# UPD70F3508 register map
Vendor: Renesas; Series: V850E2/Px4; File version: 1.0
CPU: other r0p0, little endian, no MPU, FPU, 4 interrupt priority bits
Registers are 8-bit, read-write, reset 0x0 unless marked. A register's access mark holds for its fields unless they carry their own. Offsets are from the block's base; [hi:lo] are bit positions; {n}, {i} and the like mark numbered series.

## SYSERR — System Error Notification Function Registers (Section 3.7)
Base 0xFFFF64B0
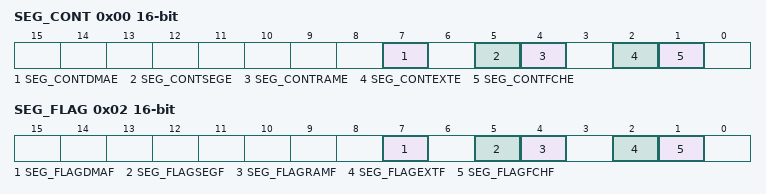
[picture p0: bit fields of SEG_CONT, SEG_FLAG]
0x00 SEG_CONT 16-bit — System Error Control Register — enables SYSERR exception generation per error source. Lower byte also accessible as SEG_CONTL (8- and 1-bit units)
  [7] SEG_CONTDMAE — DMA/DTS error notification enable: 0=SYSERR not generated, 1=SYSERR generated on DMA/DTS ECC or reserved-area error
  [5] SEG_CONTSEGE — Reserved area access notification enable: 0=SYSERR not generated, 1=SYSERR generated on CPU access to reserved/undefined area
  [4] SEG_CONTRAME — CPU on-chip RAM area error notification enable: 0=SYSERR not generated, 1=SYSERR generated on uncorrectable RAM ECC error
  [2] SEG_CONTEXTE — EXT area error notification enable: 0=SYSERR not generated, 1=SYSERR generated on data-flash error or peripheral I/O SLV/UAA/ATO error
  [1] SEG_CONTFCHE — Code flash error notification enable: 0=SYSERR not generated, 1=SYSERR generated on uncorrectable code-flash ECC error
0x02 SEG_FLAG 16-bit — System Error Flag Register — stores system error detection results. Lower byte also accessible as SEG_FLAGL (8- and 1-bit units). Cleared by read-1/write-0 sequence
  [7] SEG_FLAGDMAF — DMA/DTS error flag: set when DMA/DTS access causes code-flash ECC error, RAM ECC error, or reserved-area access
  [5] SEG_FLAGSEGF — Reserved area error flag: set when CPU accesses the reserved/undefined area
  [4] SEG_FLAGRAMF — CPU on-chip RAM area error flag: set when CPU access causes uncorrectable RAM ECC error
  [2] SEG_FLAGEXTF — EXT area error flag: set when CPU access to data-flash or peripheral I/O causes SLV/UAA/ATO/data-flash error
  [1] SEG_FLAGFCHF — Code flash error flag: set when CPU access to code-flash area causes uncorrectable ECC error

## DTFR — DMA Trigger Factor Registers and DMA Request Control
Base 0xFFFF7B00
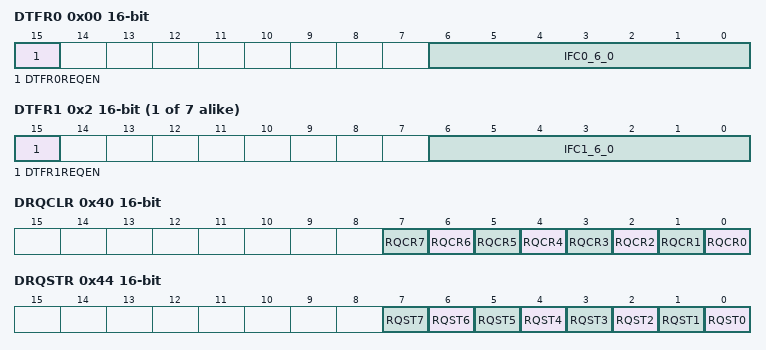
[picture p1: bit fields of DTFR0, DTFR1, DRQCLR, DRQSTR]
0x00 DTFR0 16-bit — DMA Trigger Factor Register CH0
  [15] DTFR0REQEN — DMA activating source selector enable
  [6:0] IFC0_6_0 — Transfer source select [6:0] (see Table 5-1)
{0x0+2i} DTFR{i} 16-bit (i=1..7) — DMA Trigger Factor Register CH{i}
  [15] DTFR{i}REQEN — DMA activating source selector enable
  [6:0] IFC{i}_6_0 — Transfer source select [6:0]
0x40 DRQCLR 16-bit — DMA Request Clear Register
  [n] RQCR{n} (n=0..7) — Clear DMA request for CH{n}
0x44 DRQSTR 16-bit ro — DMA Request Check Register
  [n] RQST{n} (n=0..7) — DMA transfer request pending CH{n}

## DTS — Data Transfer Service Control Registers (CPU-accessible Group A)
Base 0xFFFF7C00
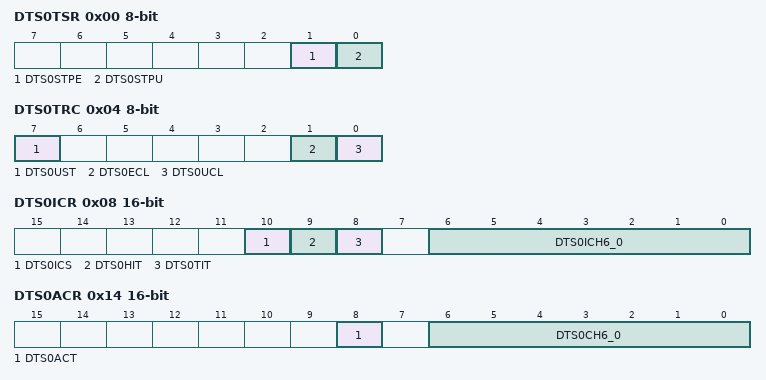
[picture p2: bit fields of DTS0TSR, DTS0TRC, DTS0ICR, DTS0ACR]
0x00 DTS0TSR ro — DTS Transfer Status Register
  [1] DTS0STPE — DTS stopped by error response
  [0] DTS0STPU — DTS stopped by user request
0x04 DTS0TRC — DTS Transfer Request Control Register
  [7] DTS0UST — DTS user stop trigger; write 1 to suspend all DTS
  [1] DTS0ECL — DTS0STPE clearing trigger; write 1 to clear error stop
  [0] DTS0UCL — DTS0STPU clearing trigger; write 1 to clear user stop
0x08 DTS0ICR 16-bit — DTS Initialization Control Register (16-bit; lower byte=DTS0ICH, upper byte=DTS0ITR)
  [10] DTS0ICS — DTS initialization channel select status
  [9] DTS0HIT — DTS TI hold init trigger; write 1 to trigger
  [8] DTS0TIT — DTS TI init trigger; write 1 to trigger
  [6:0] DTS0ICH6_0 — DTS initialization channel number [6:0]
0x0C DTS0BTR 32-bit — DTS Base Table Register — start address of DTS channel table in on-chip RAM
  [28:1] DTS0BTR28_1 — Table base address bits [28:1]; bits 31:29 and 0 are fixed 0
0x10 DTS0BVR 32-bit — DTS Base Vector Register — start address of DTS vector table in on-chip RAM
  [28:2] DTS0BVR28_2 — Vector base address bits [28:2]; bits 31:29, 1, 0 fixed 0
0x14 DTS0ACR 16-bit ro — DTS Active Channel Register
  [8] DTS0ACT — DTS active; 1 = DTS is executing
  [6:0] DTS0CH6_0 — Active channel number [6:0]
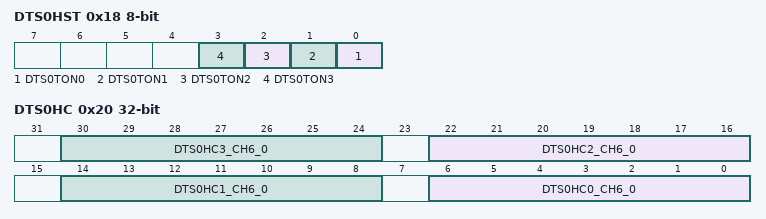
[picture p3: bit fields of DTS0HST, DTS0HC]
0x18 DTS0HST ro — DTS TI Hold Status Register
  [n] DTS0TON{n} (n=0..3) — TI hold buffer {n} occupied
0x20 DTS0HC 32-bit ro — DTS TI Hold Channel Number Register (32-bit; bytes 0..3 = HC0..HC3)
  [8n+6:8n] DTS0HC{n}_CH6_0 (n=0..3) — Hold buffer {n} channel number [6:0] (bits [{8n+6}:{8n}])
